# STM32G563 register map
File version: 2.0.0
CPU: CM33 r0p4, little endian, MPU, FPU, 4 interrupt priority bits
Registers are 32-bit, read-write, reset 0x0 unless marked. A register's access mark holds for its fields unless they carry their own. Offsets are from the block's base; [hi:lo] are bit positions.

## DCACHE — DCACHE register block
Base 0x40031400
Same registers: DCACHE_S 0x50031400
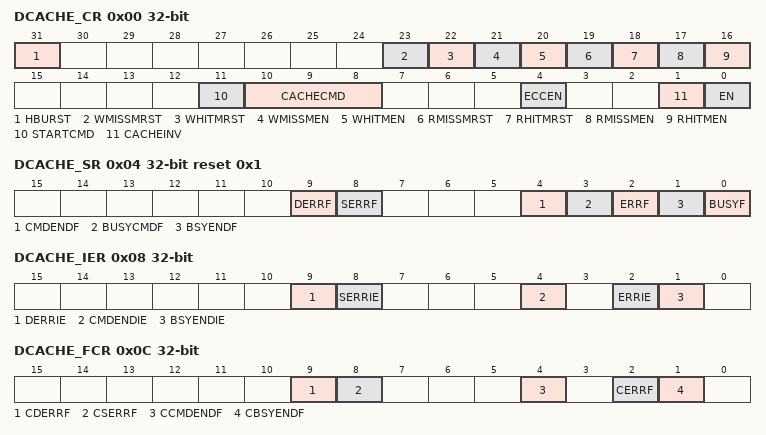
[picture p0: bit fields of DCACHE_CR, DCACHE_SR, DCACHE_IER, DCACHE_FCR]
0x00 DCACHE_CR — DCACHE control register
  [31] HBURST — output burst type for cache master port read accesses
    0=WRAP; 1=INCR
  [23] WMISSMRST — write-miss monitor reset
    0=release the cache miss monitor reset (needed to enable the counting); 1=reset cache write-miss monitor
  [22] WHITMRST — write-hit monitor reset
    0=release the cache miss monitor reset (needed to enable the counting); 1=reset cache write-hit monitor
  [21] WMISSMEN — write-miss monitor enable
    0=cache write-miss monitor switched off. Stopping the monitor does not reset it.; 1=cache write-miss monitor enabled
  [20] WHITMEN — write-hit monitor enable
    0=cache write-hit monitor switched off. Stopping the monitor does not reset it.; 1=cache write-hit monitor enabled
  [19] RMISSMRST — read-miss monitor reset
    0=release the cache miss monitor reset (needed to enable the counting); 1=reset cache read-miss monitor
  [18] RHITMRST — read-hit monitor reset
    0=release the cache miss monitor reset (needed to enable the counting); 1=reset cache read-hit monitor
  [17] RMISSMEN — read-miss monitor enable
    0=cache read-miss monitor switched off. Stopping the monitor does not reset it.; 1=cache read-miss monitor enabled
  [16] RHITMEN — read-hit monitor enable
    0=cache read-hit monitor switched off. Stopping the monitor does not reset it.; 1=cache read-hit monitor enabled
  [11] STARTCMD wo — starts maintenance command (maintenance operation defined in CACHECMD).
    0=command operation (cache maintenance) finished; 1=start maintenance command (cache maintenance)
  [10:8] CACHECMD — cache command maintenance operation (cleans and/or invalidates anaddress range)
    0=no operation; 1=clean range; 2=invalidate range; 3=clean and invalidate range
  [4] ECCEN — ECC enable
    0=ECC encoder and decoder disabled; 1=ECC encoder and decoder enabled
  [1] CACHEINV wo — full cache invalidation
    0=no effect; 1=invalidate entire cache (all cache lines valid bit and TAG/ECC/data = 0)
  [0] EN — enable
    0=cache disabled; 1=cache enabled
0x04 DCACHE_SR reset 0x1 — DCACHE status register
  [9] DERRF — ECC double-bit error flag
    0=no ECC double-bit error detected; 1=an ECC double-bit error was detected
  [8] SERRF — ECC single-bit error flag
    0=no ECC single-bit error detected; 1=an ECC single-bit error was detected
  [4] CMDENDF ro — command end flag
    0=cache busy or in idle; 1=CACHECMD command finished
  [3] BUSYCMDF ro — command busy flag
    0=cache not busy on a CACHECMD command; 1=cache busy on a CACHECMD command (clean and/or invalidate an address range)
  [2] ERRF ro — cache error flag
    0=no error; 1=an error occurred during the operation (eviction or clean operation write-back error)
  [1] BSYENDF ro — full invalidate busy end flag
    0=cache busy or in idle; 1=full invalidate CACHEINV operation finished
  [0] BUSYF ro — full invalidate busy flag
    0=cache not busy on a CACHEINV operation; 1=cache executing a full invalidate CACHEINV operation
0x08 DCACHE_IER — DCACHE interrupt enable register
  [9] DERRIE — interrupt enable on ECC double-bit error detection
    0=interrupt disabled on ECC double-bit error detection; 1=interrupt enabled on ECC double-bit error detection
  [8] SERRIE — interrupt enable on ECC single-bit error detection
    0=interrupt disabled on ECC single-bit error detection; 1=interrupt enabled on ECC single-bit error detection
  [4] CMDENDIE — interrupt enable on command end
    0=interrupt disabled on command end; 1=interrupt enabled on command end
  [2] ERRIE — interrupt enable on cache error
    0=interrupt disabled on error; 1=interrupt enabled on error
  [1] BSYENDIE — interrupt enable on busy end
    0=Interrupt disabled on busy end; 1=Interrupt enabled on busy end
0x0C DCACHE_FCR wo — DCACHE flag clear register
  [9] CDERRF — clear ECC double-bit error flag
    0=no effect; 1=clears DERRF flag in DCACHE_SR
  [8] CSERRF — clear ECC single-bit error flag
    0=no effect; 1=clears SERRF flag in DCACHE_SR
  [4] CCMDENDF — clear command end flag
    0=no effect; 1=clears CMDENDF flag in DCACHE_SR
  [2] CERRF — clear cache error flag
    0=no effect; 1=clears ERRF flag in DCACHE_SR
  [1] CBSYENDF — clear full invalidate busy end flag
    0=no effect; 1=clears BSYENDF flag in DCACHE_SR
0x10 DCACHE_RHMONR ro — DCACHE read-hit monitor register
  [31:0] RHITMON — cache read-hit monitor counter
0x14 DCACHE_RMMONR ro — DCACHE read-miss monitor register
  [15:0] RMISSMON — cache read-miss monitor counter
0x20 DCACHE_WHMONR ro — DCACHE write-hit monitor register
  [31:0] WHITMON — cache write-hit monitor counter
0x24 DCACHE_WMMONR ro — DCACHE write-miss monitor register
  [15:0] WMISSMON — cache write-miss monitor counter
0x28 DCACHE_CMDRSADDRR — DCACHE command range start address register
  [31:4] CMDSTARTADDR — start address of range to which the cache maintenance command specified in DCACHE_CR.CACHECMD field applies
0x2C DCACHE_CMDREADDRR — DCACHE command range end address register
  [31:4] CMDENDADDR — end address of range to which the cache maintenance command specified in DCACHE_CR.CACHECMD field applies
